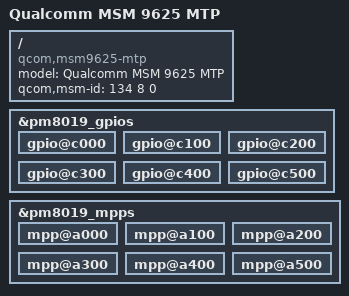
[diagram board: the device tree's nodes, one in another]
/* Copyright (c) 2012, The Linux Foundation. All rights reserved.
 *
 * This program is free software; you can redistribute it and/or modify
 * it under the terms of the GNU General Public License version 2 and
 * only version 2 as published by the Free Software Foundation.
 *
 * This program is distributed in the hope that it will be useful,
 * but WITHOUT ANY WARRANTY; without even the implied warranty of
 * MERCHANTABILITY or FITNESS FOR A PARTICULAR PURPOSE.  See the
 * GNU General Public License for more details.
 */

/dts-v1/;

/include/ "msm9625.dtsi"

/ {
	model = "Qualcomm MSM 9625 MTP";
	compatible = "qcom,msm9625-mtp", "qcom,msm9625";
	qcom,msm-id = <134 8 0>;
};

/* PM8019 GPIO and MPP configuration */
&pm8019_gpios {
	gpio@c000 { /* GPIO 1 */
	};

	gpio@c100 { /* GPIO 2 */
	};

	gpio@c200 { /* GPIO 3 */
	};

	gpio@c300 { /* GPIO 4 */
	};

	gpio@c400 { /* GPIO 5 */
	};

	gpio@c500 { /* GPIO 6 */
	};
};

&pm8019_mpps {
	mpp@a000 { /* MPP 1 */
	};

	mpp@a100 { /* MPP 2 */
	};

	mpp@a200 { /* MPP 3 */
	};

	mpp@a300 { /* MPP 4 */
	};

	mpp@a400 { /* MPP 5 */
	};

	mpp@a500 { /* MPP 6 */
	};
};
